# STM32F101xG register map
File version: 1.0
Registers are 32-bit, read-write, reset 0x0 unless marked. A register's access mark holds for its fields unless they carry their own. Offsets are from the block's base; [hi:lo] are bit positions; {n}, {i} and the like mark numbered series; 'fields as' and 'values as' point back to an identical list.

## GPIOA — General Purpose I/O
Base 0x40010800
Same registers: GPIOB 0x40010C00, GPIOC 0x40011000, GPIOD 0x40011400, GPIOE 0x40011800, GPIOF 0x40011C00, GPIOG 0x40012000
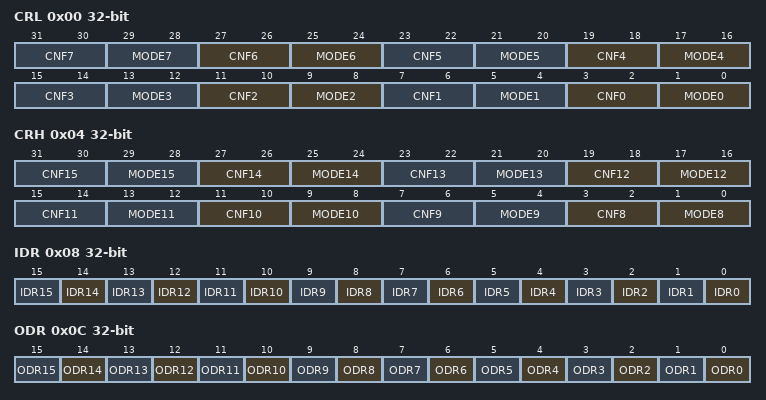
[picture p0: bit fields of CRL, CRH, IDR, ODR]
0x00 CRL
  [4n+3:4n+2] CNF{n} (n=0..7) — CNF{n}[1:0] bits (Port x configuration bits, pin {n})
  [4n+1:4n] MODE{n} (n=0..7) — MODE{n}[1:0] bits (Port x mode bits, pin {n})
0x04 CRH
  [4n-29:4n-30] CNF{n} (n=8..15) — CNF{n}[1:0] bits (Port x configuration bits, pin {n})
  [4n-31:4n-32] MODE{n} (n=8..15) — MODE{n}[1:0] bits (Port x mode bits, pin {n})
0x08 IDR
  [n] IDR{n} (n=0..15) — Port input data, bit {n}
0x0C ODR
  [n] ODR{n} (n=0..15) — Port output data, bit {n}
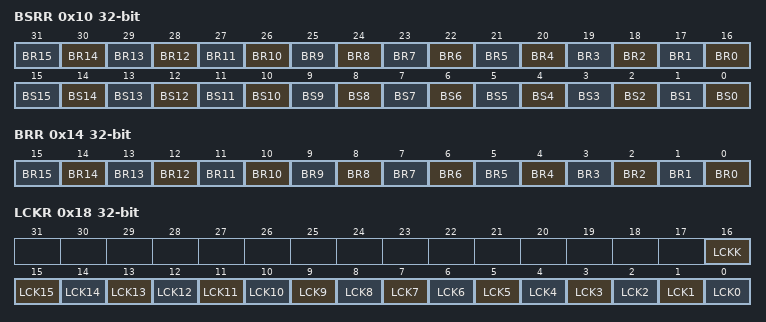
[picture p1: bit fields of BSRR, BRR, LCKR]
0x10 BSRR
  [n+16] BR{n} (n=0..15) — Port x Reset bit {n}
  [n] BS{n} (n=0..15) — Port x Set bit {n}
0x14 BRR
  [n] BR{n} (n=0..15) — Port x Reset bit {n}
0x18 LCKR
  [16] LCKK — Lock key
  [n] LCK{n} (n=0..15) — Port x Lock bit {n}

## DMA1
Base 0x40020000
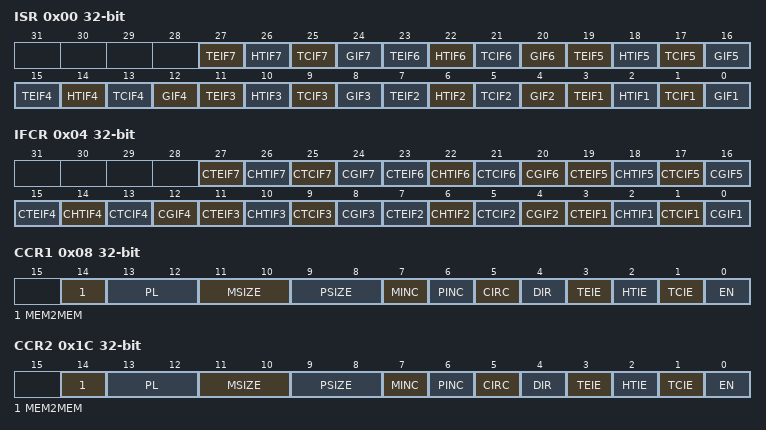
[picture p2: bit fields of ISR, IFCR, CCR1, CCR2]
0x00 ISR
  [4n-1] TEIF{n} (n=1..7) — Channel {n} Transfer Error flag
  [4n-2] HTIF{n} (n=1..7) — Channel {n} Half Transfer flag
  [4n-3] TCIF{n} (n=1..7) — Channel {n} Transfer Complete flag
  [4n-4] GIF{n} (n=1..7) — Channel {n} Global interrupt flag
0x04 IFCR
  [4n-1] CTEIF{n} (n=1..7) — Channel {n} Transfer Error clear
  [4n-2] CHTIF{n} (n=1..7) — Channel {n} Half Transfer clear
  [4n-3] CTCIF{n} (n=1..7) — Channel {n} Transfer Complete clear
  [4n-4] CGIF{n} (n=1..7) — Channel {n} Global interrupt clear
0x08 CCR1
  [14] MEM2MEM — Memory to memory mode
  [13:12] PL — PL[1:0] bits(Channel Priority level)
  [11:10] MSIZE — MSIZE[1:0] bits (Memory size)
  [9:8] PSIZE — PSIZE[1:0] bits (Peripheral size)
  [7] MINC — Memory increment mode
  [6] PINC — Peripheral increment mode
  [5] CIRC — Circular mode
  [4] DIR — Data transfer direction
  [3] TEIE — Transfer error interrupt enable
  [2] HTIE — Half Transfer interrupt enable
  [1] TCIE — Transfer complete interrupt enable
  [0] EN — Channel enable
0x0C CNDTR1
  [15:0] NDT — Number of data to Transfer
0x10 CPAR1
  [31:0] PA — Peripheral Address
{0x0+0x14*i} CMAR{i} (i=1..7)
  [31:0] MA — Memory Address
0x1C CCR2
  fields as CCR1
0x20 CNDTR2
  [15:0] NDT — Number of data to Transfer
0x24 CPAR2
  [31:0] PA — Peripheral Address
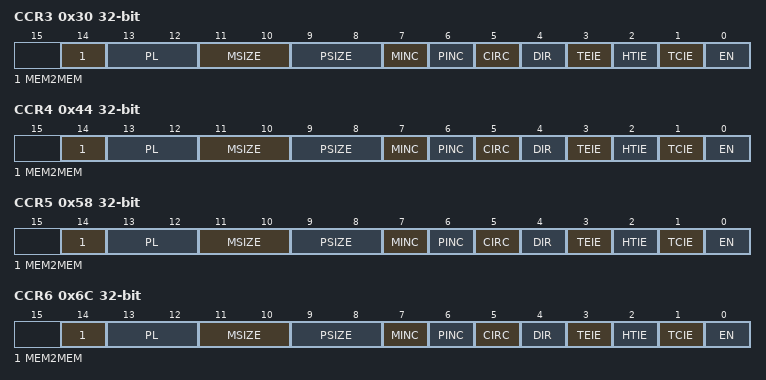
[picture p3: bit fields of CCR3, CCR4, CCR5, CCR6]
0x30 CCR3
  fields as CCR1
0x34 CNDTR3
  [15:0] NDT — Number of data to Transfer
0x38 CPAR3
  [31:0] PA — Peripheral Address
0x44 CCR4
  fields as CCR1
0x48 CNDTR4
  [15:0] NDT — Number of data to Transfer
0x4C CPAR4
  [31:0] PA — Peripheral Address
0x58 CCR5
  fields as CCR1
0x5C CNDTR5
  [15:0] NDT — Number of data to Transfer
0x60 CPAR5
  [31:0] PA — Peripheral Address
0x6C CCR6
  fields as CCR1
0x70 CNDTR6
  [15:0] NDT — Number of data to Transfer
0x74 CPAR6
  [31:0] PA — Peripheral Address
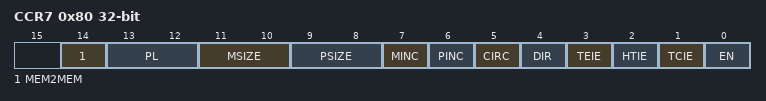
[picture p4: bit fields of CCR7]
0x80 CCR7
  fields as CCR1
0x84 CNDTR7
  [15:0] NDT — Number of data to Transfer
0x88 CPAR7
  [31:0] PA — Peripheral Address

## DMA2
Base 0x40020400
Registers as DMA1, without CCR6, CNDTR6, CPAR6, CMAR6, CCR7, CNDTR7, CPAR7, CMAR7.

## FLASH — FLASH Registers
Base 0x40022000
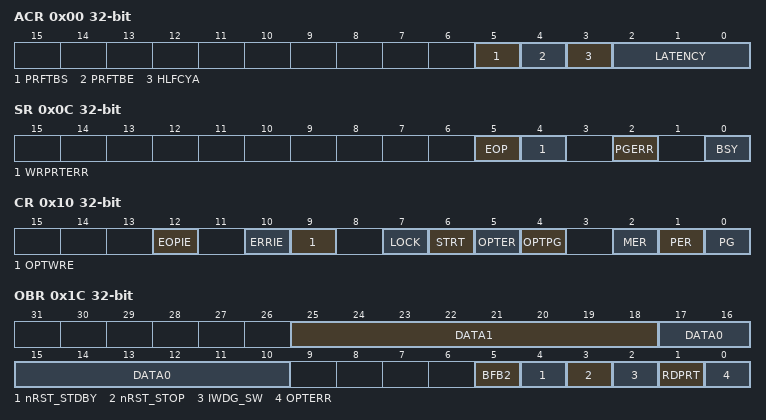
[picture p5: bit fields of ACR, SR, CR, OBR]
0x00 ACR
  [5] PRFTBS — Prefetch Buffer Status
  [4] PRFTBE — Prefetch Buffer Enable
  [3] HLFCYA — Flash Half Cycle Access Enable
  [2:0] LATENCY — LATENCY[2:0] bits (Latency)
    0=FLASH Zero Latency cycle; 1=FLASH One Latency cycle; 2=FLASH Two wait states
0x04 KEYR
  [31:0] FKEYR — FPEC Key
0x08 OPTKEYR
  [31:0] OPTKEYR — Option Byte Key
0x0C SR
  [5] EOP — End of operation
  [4] WRPRTERR — Write Protection Error
  [2] PGERR — Programming Error
  [0] BSY — Busy
0x10 CR
  [12] EOPIE — End of operation interrupt enable
  [10] ERRIE — Error Interrupt Enable
  [9] OPTWRE — Option Bytes Write Enable
  [7] LOCK
  [6] STRT — Start
  [5] OPTER — Option Byte Erase
  [4] OPTPG — Option Byte Programming
  [2] MER — Mass Erase
  [1] PER — Page Erase
  [0] PG — Programming
0x14 AR
  [31:0] FAR — Flash Address
0x1C OBR
  [25:18] DATA1
  [17:10] DATA0
  [5] BFB2
  [4] nRST_STDBY
  [3] nRST_STOP
  [2] IWDG_SW
  [1] RDPRT — Read protection
  [0] OPTERR — Option Byte Error
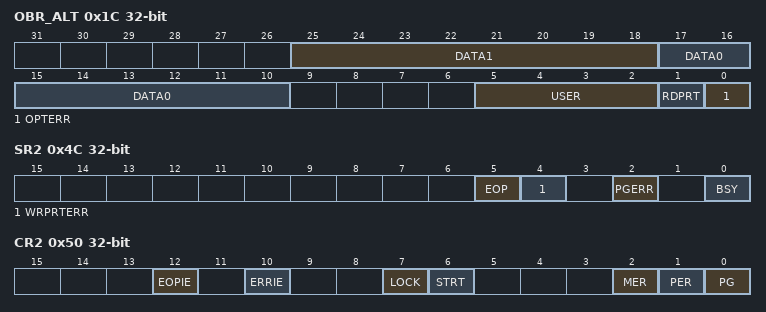
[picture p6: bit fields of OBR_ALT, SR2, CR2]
0x1C OBR_ALT (alternate view of OBR)
  [25:18] DATA1
  [17:10] DATA0
  [5:2] USER — User Option Bytes
  [1] RDPRT — Read protection
  [0] OPTERR — Option Byte Error
0x20 WRPR
  [31:0] WRP — Write Protect
0x44 KEYR2
  [31:0] FKEYR — FPEC Key
0x4C SR2
  fields as SR
0x50 CR2
  [12] EOPIE — End of operation interrupt enable
  [10] ERRIE — Error Interrupt Enable
  [7] LOCK
  [6] STRT — Start
  [2] MER — Mass Erase
  [1] PER — Page Erase
  [0] PG — Programming
0x54 AR2
  [31:0] FAR — Flash Address
